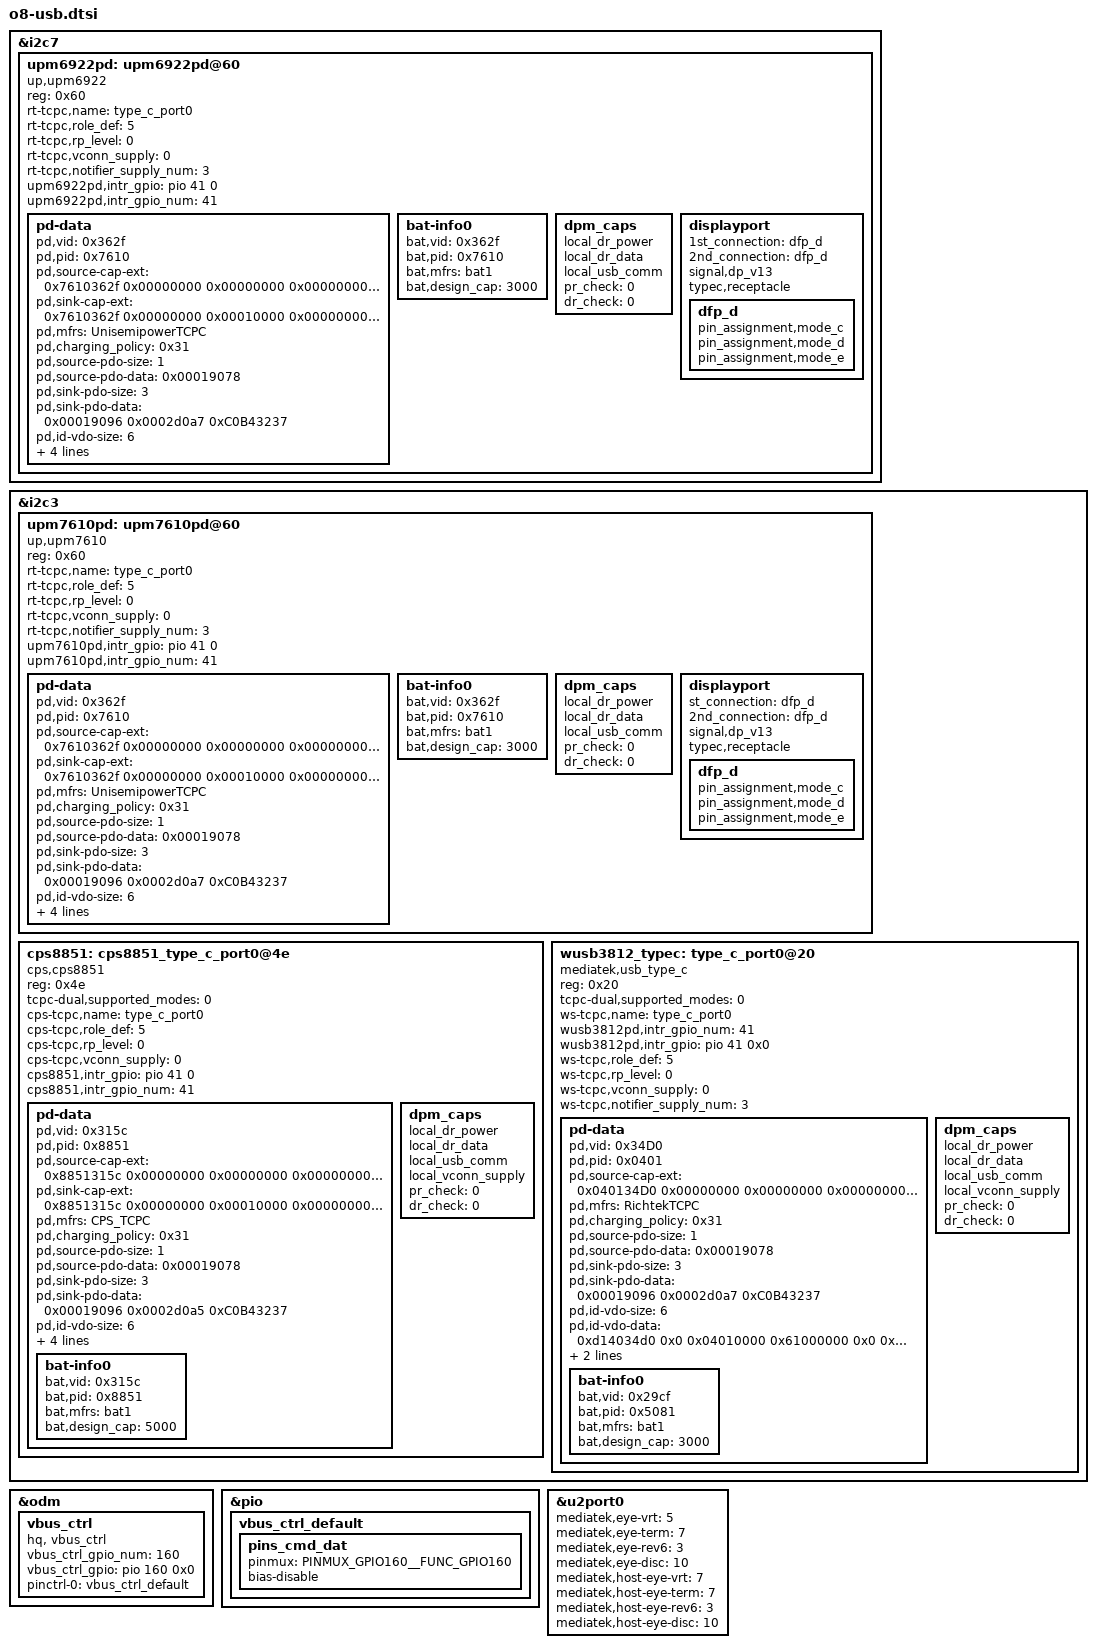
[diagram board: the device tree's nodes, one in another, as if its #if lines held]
/* A06 code for SR-AL7160A-01-347 by shixuaxnuan at 20240313 start */
/* Note for tcpc data
* tcpc-dual,supported_modes : 0: dfp/ufp, 1: dfp, 2: ufp
* *-tcpc,role_def : 0: Unknown, 1: SNK, 2: SRC 3: DRP, 4: Try.SRC, 5: Try.SNK
* *-tcpc,rp_level: 0: Default, 1: 1.5, 2: 3.0
* *-tcpc,vconn_supply : 0: Never, 1: Always, 2: EMarkOnly, 3: StartOnly
* *-pd,charging_policy: VSAFE5V = 0, MAX_POWER = 1, CUSTOM = 2,MAX_POWER_LV = 0x21,
*     											MAX_POWER_LVIC = 0x31, MAX_POWER_HV = 0x41, MAX_POWER_HVIC = 0x51
* pd,sink-pdo-data: Fixed 5V, 500 mA <0x00019032>, Fixed 5V, 1A <0x00019064>, Fixed 5V, 2A <0x000190c8>
*	              						Fixed 5V, 3A <0x0001912c>, Fixed 9V, 500 mA <0x0002d032>, Fixed 9V, 1A <0x0002d064>
*                						Fixed 9V, 2A <0x0002d0c8>, Fixed 9V, 3A <0x0002d12c>, Variable 5-9V, 1A <0x8642d064>
*                						Variable 5-9V, 2A <0x8642d0c8>, Variable 5-9V, 3A <0x8642d12c>, PPS 3V~5.9V, 3A <0xC0761E3C>
* No DP, host + device: pd,id-vdo-size = <6>;
*										 	  pd,id-vdo-data = <0xd14029cf 0x0 0x17110000
*                            				  										0x41800000 0x0 0x21800000>;
* With DP: pd,id-vdo-size = <6>;
*                	pd,id-vdo-data = <0xd54029cf 0x0 0x17110000
*                            							  0x41800000 0x0 0x21800000>;
*/

&i2c7 {
    upm6922pd: upm6922pd@60{
        compatible = "up,upm6922";
        reg = <0x60>;
        status = "okay";
        rt-tcpc,name = "type_c_port0";
        rt-tcpc,role_def = <5>;
        rt-tcpc,rp_level = <0>;
        rt-tcpc,vconn_supply  = <0>;
#if (CONFIG_MTK_GAUGE_VERSION == 30)
        rt-tcpc,notifier_supply_num = <3>;
#else
        rt-tcpc,notifier_supply_num = <2>;
#endif
        upm6922pd,intr_gpio = <&pio 41 0>;
        upm6922pd,intr_gpio_num = <41>;
        pd-data {
            pd,vid = <0x362f>;
            pd,pid = <0x7610>;
            pd,source-cap-ext = <0x7610362f 0x00000000 0x00000000
                        0x00000000 0x00000000 0x06000000 0x00>;
            pd,sink-cap-ext = <0x7610362f 0x00000000 0x00010000
                        0x00000000 0x19020400 0x00000019>;
            pd,mfrs = "UnisemipowerTCPC";
            pd,charging_policy= <0x31>;

            pd,source-pdo-size = <1>;
            pd,source-pdo-data = <0x00019078>;
            pd,sink-pdo-size = <3>;
            pd,sink-pdo-data = <0x00019096 0x0002d0a7 0xC0B43237>; //5V,1.5A 9V,1.67A pps 5~9V,2.75A

            pd,id-vdo-size = <6>;
            pd,id-vdo-data = <0xd140362f 0x0 0x76100000
                        0x41800000 0x0 0x21800000>;

            bat,nr = <1>;
            pd,country_nr = <0>;
        };

        bat-info0 {
            bat,vid = <0x362f>;
            bat,pid = <0x7610>;
            bat,mfrs = "bat1";
            bat,design_cap = <3000>;
        };

        dpm_caps {
            local_dr_power;
            local_dr_data;
            local_usb_comm;

            pr_check = <0>; // 0: disable, 1: prefer_snk, 2: prefer_src
            dr_check = <0>; // 0: disable, 1: prefer_ufp, 2: prefer_dfp
        };

        displayport {
            1st_connection = "dfp_d";
            2nd_connection = "dfp_d";
            signal,dp_v13;
            typec,receptacle;
            dfp_d {
                pin_assignment,mode_c;
                pin_assignment,mode_d;
                pin_assignment,mode_e;
            };
        };
    };
};
/* A06 code for SR-AL7160A-01-347 by shixuaxnuan at 20240313 end */
/* A06 code for SR-AL7160A-01-275 by shixuaxnuan at 20240325 start */
&i2c3 {
    upm7610pd: upm7610pd@60{
        compatible = "up,upm7610";
        reg = <0x60>;
        status = "okay";
        rt-tcpc,name = "type_c_port0";
        rt-tcpc,role_def = <5>;
        rt-tcpc,rp_level = <0>;
        rt-tcpc,vconn_supply  = <0>;
#if (CONFIG_MTK_GAUGE_VERSION == 30)
        rt-tcpc,notifier_supply_num = <3>;
#else
        rt-tcpc,notifier_supply_num = <2>;
#endif
        upm7610pd,intr_gpio = <&pio 41 0>;
        upm7610pd,intr_gpio_num = <41>;
        pd-data {
            pd,vid = <0x362f>;
            pd,pid = <0x7610>;
            pd,source-cap-ext = <0x7610362f 0x00000000 0x00000000
                        0x00000000 0x00000000 0x06000000 0x00>;
            pd,sink-cap-ext = <0x7610362f 0x00000000 0x00010000
                        0x00000000 0x19020400 0x00000019>;
            pd,mfrs = "UnisemipowerTCPC";
            pd,charging_policy= <0x31>;

            pd,source-pdo-size = <1>;
            pd,source-pdo-data = <0x00019078>;
            pd,sink-pdo-size = <3>;
            pd,sink-pdo-data = <0x00019096 0x0002d0a7 0xC0B43237>; //5V,1.5A 9V,1.67A

            pd,id-vdo-size = <6>;
            pd,id-vdo-data = <0xd140362f 0x0 0x76100000
                    0x41800000 0x0 0x21800000 0x0>;

            bat,nr = <1>;
            pd,country_nr = <0>;
        };

        bat-info0 {
            bat,vid = <0x362f>;
            bat,pid = <0x7610>;
            bat,mfrs = "bat1";
            bat,design_cap = <3000>;
        };

        dpm_caps {
            local_dr_power;
            local_dr_data;
            local_usb_comm;

            pr_check = <0>; // 0: disable, 1: prefer_snk, 2: prefer_src
            dr_check = <0>; // 0: disable, 1: prefer_ufp, 2: prefer_dfp
        };

        displayport {
            st_connection = "dfp_d";
            2nd_connection = "dfp_d";
            signal,dp_v13;
            typec,receptacle;
            dfp_d {
                pin_assignment,mode_c;
                pin_assignment,mode_d;
                pin_assignment,mode_e;
            };
        };
    };
    /* A06 code for SR-AL7160A-01-274 by shixuanxuan at 20240326 start */
    cps8851:cps8851_type_c_port0@4e{
        compatible = "cps,cps8851";
        reg = <0x4e>;
        status = "okay";
        tcpc-dual,supported_modes = <0>;
        cps-tcpc,name = "type_c_port0";
        cps-tcpc,role_def = <5>;
        cps-tcpc,rp_level = <0>;
        cps-tcpc,vconn_supply  = <0>;
        cps8851,intr_gpio = <&pio 41 0>;
        cps8851,intr_gpio_num = <41>;
        pd-data {
            pd,vid = <0x315c>;
            pd,pid = <0x8851>;
            pd,source-cap-ext = <0x8851315c 0x00000000 0x00000000
                        0x00000000 0x00000000 0x06000000 0x00000000>;
            pd,sink-cap-ext = <0x8851315c 0x00000000 0x00010000
                        0x00000000 0x05000000 0x0000000f>;
            pd,mfrs = "CPS_TCPC";
            pd,charging_policy= <0x31>;
            pd,source-pdo-size = <1>;
            pd,source-pdo-data = <0x00019078>;
            pd,sink-pdo-size = <3>;
            pd,sink-pdo-data = <0x00019096 0x0002d0a5 0xC0B43237>; // 9V1.65A
            pd,id-vdo-size = <6>;
            pd,id-vdo-data = <0xd140315c 0x0 0x88510000
                0x61000000 0x0 0x41000000>;

            bat,nr = <1>;
            pd,country_nr = <0>;

            bat-info0 {
                bat,vid = <0x315c>;
                bat,pid = <0x8851>;
                bat,mfrs = "bat1";
                bat,design_cap = <5000>;
            };
        };
        dpm_caps {
            local_dr_power;
            local_dr_data;
            local_usb_comm;
            local_vconn_supply;
            pr_check = <0>;
            dr_check = <0>;
        };
    };
    /* A06 code for SR-AL7160A-01-274 by shixuanxuan at 20240326 end */

    /* A06 code for SR-AL7160A-01-291 by zhangziyi at 20240327 start */
    /* A06 code for SR-AL7160A-01-287 by shixuanxuan at 20240419 start*/
        wusb3812_typec: type_c_port0@20 {
        reg = <0x20>;
        compatible = "mediatek,usb_type_c";
        status = "okay";
        tcpc-dual,supported_modes = <0>;
        ws-tcpc,name = "type_c_port0";
        wusb3812pd,intr_gpio_num = <41>;
        wusb3812pd,intr_gpio = <&pio 41 0x0>;
        ws-tcpc,role_def = <5>;
        ws-tcpc,rp_level = <0>;
        ws-tcpc,vconn_supply  = <0>;

        ws-tcpc,notifier_supply_num = <3>;

        pd-data {
            pd,vid = <0x34D0>;
            pd,pid = <0x0401>;
            pd,source-cap-ext = <0x040134D0 0x00000000 0x00000000
                            0x00000000 0x00000000 0x07010000 >;
            pd,mfrs = "RichtekTCPC";
            pd,charging_policy= <0x31>;

            pd,source-pdo-size = <1>;
            /*pd,source-pdo-data = <0x00019032>; kelong modify2*/
            pd,source-pdo-data = <0x00019078>;

            /*pd,sink-pdo-size = <2>;   kelong modify3
            pd,sink-pdo-data = <0x000190c8 0x0002d0a5> ; //5V,2A 9V,1.67A  */
            pd,sink-pdo-size = <3>;
            pd,sink-pdo-data = <0x00019096 0x0002d0a7 0xC0B43237>; // 9V1.65A
            /*pd,sink-pdo-data = <0x00019096 0x0002d0a5 0xC0B43237>; // 9V1.65A kelong modify4*/

            pd,id-vdo-size = <6>;
            pd,id-vdo-data = <0xd14034d0 0x0 0x04010000
                0x61000000 0x0 0x41000000>;
            bat,nr = <1>;
            pd,country_nr = <0>;

            bat-info0 {
                bat,vid = <0x29cf>;
                bat,pid = <0x5081>;
                bat,mfrs = "bat1";
                bat,design_cap = <3000>;
            };
        };
        dpm_caps {
            local_dr_power;
            local_dr_data;
            local_usb_comm;
            local_vconn_supply;
            pr_check = <0>; // 0: disable, 1: prefer_snk, 2: prefer_src
            dr_check = <0>; // 0: disable, 1: prefer_ufp, 2: prefer_dfp
        };
    };
    /* A06 code for SR-AL7160A-01-287 by shixuanxuan at 20240419 end*/
    /* A06 code for SR-AL7160A-01-291 by zhangziyi at 20240327 end */
};
/* A06 code for SR-AL7160A-01-275 by shixuaxnuan at 20240325 end */
/* hs14 code for SR-AL6528A-01-305 by shanxinkai at 2022/09/06 start */
&odm {
    /* VBUS control */
    vbus_ctrl: vbus_ctrl {
        compatible = "hq, vbus_ctrl";
        vbus_ctrl_gpio_num = <160>;
        vbus_ctrl_gpio = <&pio 160 0x0>;
        pinctrl-names = "default";
        pinctrl-0 = <&vbus_ctrl_default>;
    };
};

&pio {
    vbus_ctrl_default: vbus_ctrl_default {
        pins_cmd_dat {
            pinmux = <PINMUX_GPIO160__FUNC_GPIO160>;
            bias-disable;
        };
    };
};
/* hs14 code for SR-AL6528A-01-305 by shanxinkai at 2022/09/06 end */

/* A06 code for AL7160A-43 by zhangziyi at 20240407 start */
/* hs14 code for AL6528A-30 by wenyaqi at 2022/09/11 start */
&u2port0 {
    /*A06 code for P240624-09155 by shixuanxuan at 20240629 start*/
    mediatek,eye-vrt = <5>; /* 0~7 */
    /*A06 code for P240624-09155 by shixuanxuan at 20240629 end*/
    mediatek,eye-term = <7>; /* 0~7 */
    mediatek,eye-rev6 = <3>; /* 0~3 */
    /* hs14 code for SR-AL6528A-01-253 by chengyuanhang at 2022/09/23 start */
    mediatek,eye-disc = <10>; /* 0~8 */
    /* hs14 code for SR-AL6528A-01-253 by chengyuanhang at 2022/09/23 end */
    mediatek,host-eye-vrt = <7>; /* 0~7 */
    mediatek,host-eye-term = <7>; /* 0~7 */
    mediatek,host-eye-rev6 = <3>; /* 0~3 */
    /* hs14 code for SR-AL6528A-01-253 by chengyuanhang at 2022/09/23 start */
    mediatek,host-eye-disc = <10>; /* 0~8 */
    /* hs14 code for SR-AL6528A-01-253 by chengyuanhang at 2022/09/23 end */
};
/* A06 code for AL7160A-43 by zhangziyi at 20240407 end */
